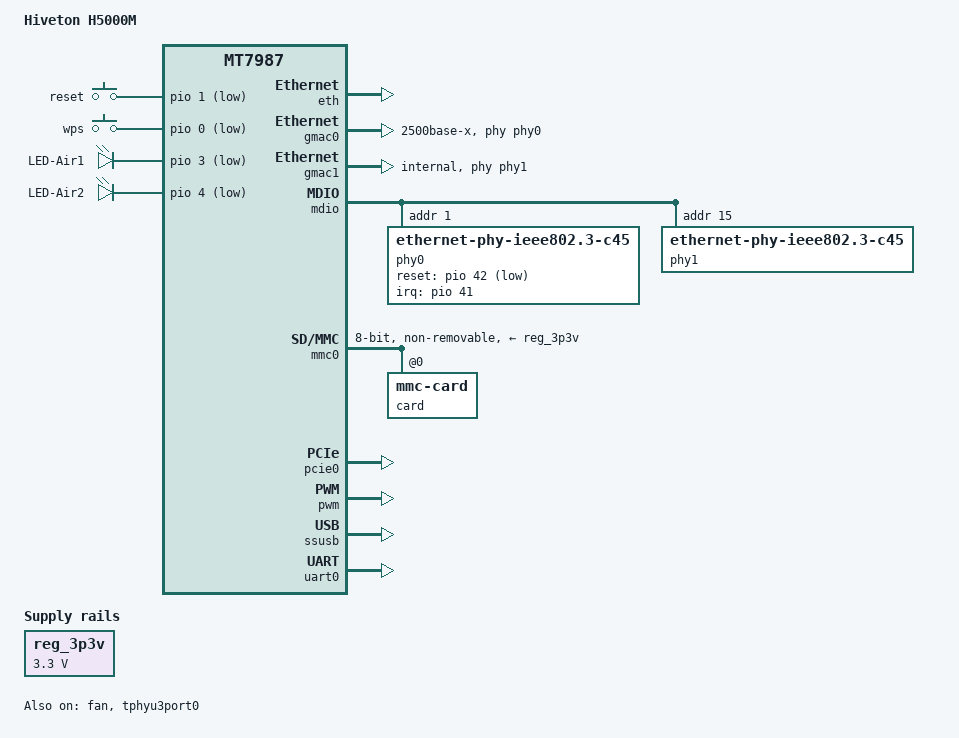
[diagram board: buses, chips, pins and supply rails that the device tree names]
// SPDX-License-Identifier: (GPL-2.0 OR MIT)
/*
 * Copyright (C) 2025 MediaTek Inc.
 * Author: Sam.Shih <sam.shih@mediatek.com>
 */

/dts-v1/;
#include "mt7987a.dtsi"
#include <dt-bindings/input/input.h>

/* MT7987A RFB DTS for DT overlay-based device tree */
/ {
	model = "Hiveton H5000M";
	compatible = "hiveton,h5000m", "mediatek,mt7987";

	chosen {
		bootargs = "console=ttyS0,115200n1 loglevel=8  \
			    earlycon=uart8250,mmio32,0x11000000 \
			    pci=pcie_bus_perf \
			    root=PARTLABEL=rootfs rootwait \
			    rootfstype=squashfs,f2fs";
	};

	gpio-keys {
		compatible = "gpio-keys";

		reset {
			label = "reset";
			linux,code = <KEY_RESTART>;
			gpios = <&pio 1 GPIO_ACTIVE_LOW>;
			debounce-interval = <10>;
		};

		wps {
			label = "wps";
			linux,code = <KEY_WPS_BUTTON>;
			gpios = <&pio 0 GPIO_ACTIVE_LOW>;
			debounce-interval = <10>;
		};
	};

	leds {
		compatible = "gpio-leds";

		led_air1: led-air1 {
			label = "LED-Air1";
			gpios = <&pio 3 GPIO_ACTIVE_LOW>;
			default-state = "off";
		};

		led_air2: led-air2 {
			label = "LED-Air2";
			gpios = <&pio 4 GPIO_ACTIVE_LOW>;
			default-state = "off";
		};
	};

	/* use pwm0 as led: share with fan/pwm_rgb */
	pwm_led {
		pinctrl-names = "default";
		pinctrl-0 = <&pwm_pins>;
		status = "okay";

		led {
			pwms = <&pwm 0 50000 0>;
			max-brightness = <255>;
			active-low;
			linux,default-trigger = "default-on";
		};
	};

	/* use pwm0/1/2 as multicolor LED: share with fan/pwm_led */
	pwm_rgb {
		pinctrl-names = "default";
		pinctrl-0 = <&pwm_rgb_pins>;
		status = "disabled";

		multi-led {
			color = <LED_COLOR_ID_RGB>;
			function = LED_FUNCTION_INDICATOR;
			max-brightness = <255>;

			led-red {
				pwms = <&pwm 0 50000>;
				color = <LED_COLOR_ID_RED>;
			};

			led-green {
				pwms = <&pwm 1 50000>;
				color = <LED_COLOR_ID_GREEN>;
			};

			led-blue {
				pwms = <&pwm 2 50000>;
				color = <LED_COLOR_ID_BLUE>;
			};
		};
	};

	reg_3p3v: regulator-3p3v {
		compatible = "regulator-fixed";
		regulator-name = "fixed-3.3V";
		regulator-min-microvolt = <3300000>;
		regulator-max-microvolt = <3300000>;
		regulator-boot-on;
		regulator-always-on;
	};	
};

&eth {
	status = "okay";
};

&fan {
	pinctrl-names = "default";
	pinctrl-0 = <&pwm_fan_pins>;
	pwms = <&pwm 1 50000 0>;
	status = "okay";
};

&gmac0 {
	phy-mode = "2500base-x";
	phy-handle = <&phy0>;
	status = "okay";
};

&gmac1 {
	phy-mode = "internal";
	phy-handle = <&phy1>;
	status = "okay";
};

&mdio {
	/* RTL8221B-VB-CG 2.5Gbps PHY (right) eth0 */
	phy0: phy@1 {
		reg = <1>;
		compatible = "ethernet-phy-ieee802.3-c45";
		reset-gpios = <&pio 42 GPIO_ACTIVE_LOW>;
		reset-assert-us = <100000>;
		reset-deassert-us = <100000>;
		realtek,aldps-enable;
		interrupt-parent = <&pio>;
		interrupts = <41 IRQ_TYPE_LEVEL_LOW>;
	};

	/* built-in 2.5G Ethernet PHY (left) eth1 */
	phy1: phy@15 {
		reg = <15>;
		compatible = "ethernet-phy-ieee802.3-c45";
		pinctrl-names = "i2p5gbe-led";
		pinctrl-0 = <&i2p5gbe_led0_pins>;
	};
};

&mmc0 {
	pinctrl-names = "default", "state_uhs";
	pinctrl-0 = <&mmc_pins_default>;
	pinctrl-1 = <&mmc_pins_uhs>;
	bus-width = <8>;
	max-frequency = <48000000>;
	cap-mmc-highspeed;
	vmmc-supply = <&reg_3p3v>;
	non-removable;
	status = "okay";

	card@0 {
		compatible = "mmc-card";
		reg = <0>;

		block {
			compatible = "block-device";
		};
	};
};

&pcie0 {
	pinctrl-names = "default";
	pinctrl-0 = <&pcie0_pins>;
	status = "okay";
};

&pcie1 {
	pinctrl-names = "default";
	pinctrl-0 = <&pcie1_pins>;
	status = "disabled";
};

&pio {
	pwm_fan_pins: pwm-fan-pins {
		mux {
			function = "pwm";
			groups = "pwm1_0";
		};
	};
};

&pwm {
	status = "okay";
};

&spi1 {
	status = "disabled";
};

&ssusb {
	status = "okay";
};

&tphyu3port0 {
	status = "okay";
};

&uart0 {
	pinctrl-names = "default";
	pinctrl-0 = <&uart0_pins>;
	status = "okay";
};
